# K1921VG015 register map
Vendor: NIIET; Series: K1921Vxxx; File version: 1.14
Registers are 32-bit, read-write, reset 0x0 unless marked. A register's access mark holds for its fields unless they carry their own. Offsets are from the block's base; [hi:lo] are bit positions; lines under a group give offsets from that group; {n}, {i} and the like mark numbered series; 'fields as' and 'values as' point back to an identical list.

## IWDT — Watchdog control registers
Base 0x38012000
0x00 LOAD — Watchdog Load Register
  [31:0] VAL
0x04 VALUE ro — Watchdog Value Register
  [31:0] VAL
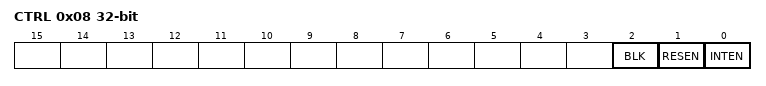
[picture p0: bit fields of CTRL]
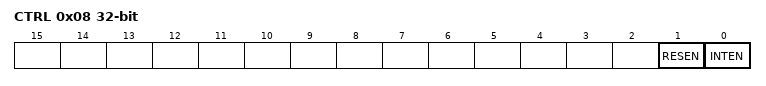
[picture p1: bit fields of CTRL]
0x08 CTRL — Watchdog Control Register
  [2] BLK — Blocking configuration
  [1] RESEN — Enable watchdog reset output
  [0] INTEN — Enable the interrupt event
0x0C INTCLR wo — Watchdog Clear Interrupt Register
  [31:0] WDTCLR
0x10 RIS ro — Watchdog Raw Interrupt Status Register
  [0] RAWWDTINT — Raw interrupt status from the counter
0x14 MIS ro — Watchdog Interrupt Status Register
  [0] WDTINT — Enabled interrupt status from the counter
0xC00 LOCK wo — Watchdog Lock Register
  [0] REGWRDIS — Disable write to all registers Watchdog

## WDT — Watchdog control registers
Base 0x3000B000
Registers as IWDT; these are added or differ:
0x08 CTRL — Watchdog Control Register
  [1] RESEN — Enable watchdog reset output
  [0] INTEN — Enable the interrupt event
0x0C INTCLR wo — Watchdog Clear Interrupt Register
  [31:0] WDTCLR
0x14 MIS ro — Watchdog Interrupt Status Register
  [0] WDTINT — Enabled interrupt status from the counter

## TMR0 — TMR 16-bit controller registers
Base 0x30001000
Same registers: TMR1 0x30002000, TMR2 0x30003000
0x00 CTRL — Timer control register
  [8] CLKSEL — Clock Source Select
    0=SysClk (Select system Clk); 1=ExtClk (Select External Clk)
  [7:6] DIV — Divider
    0=Clock not divided; 1=Clock divided by 2; 2=Clock divided by 4; 3=Clock divided by 8
  [5:4] MODE — Count mode
    0=Stop (Timer is Stopped); 1=Up (Timer count Up); 2=Multiple (Timer count is multiple Up); 3=UpDown (Timer count is multiple Up - Down)
  [2] CLR — Timer Clear
0x04 COUNT — Current value timer register
  [15:0] VAL
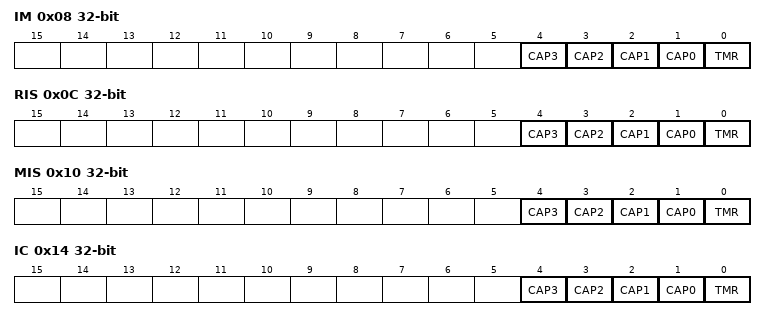
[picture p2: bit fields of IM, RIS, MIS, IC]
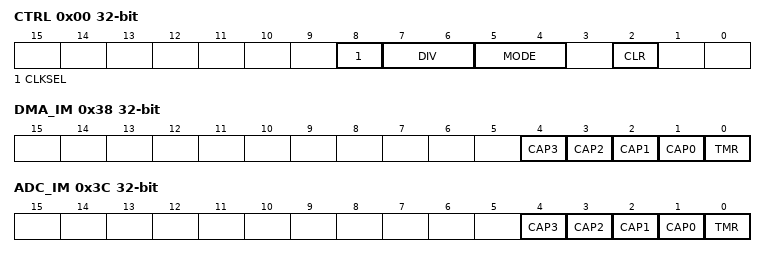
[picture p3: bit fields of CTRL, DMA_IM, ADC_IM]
0x08 IM — Interrupt mask register
  [n+1] CAP{n} (n=0..3) — Capcom{n} Interrupt Enable
  [0] TMR — Timer Interrupt Enable
0x0C RIS ro — Raw Interrupt Status register
  [n+1] CAP{n} (n=0..3) — Capcom{n} Interrupt Status
  [0] TMR — Timer Interrupt Status
0x10 MIS ro — Masked Interrupt Status register
  fields as RIS
0x14 IC wo — Clear Interrupt Status register
  [n+1] CAP{n} (n=0..3) — Capcom{n} Interrupt Clear
  [0] TMR — Timer Interrupt Clear
{0x18+8i} CAPCOM[{i}] (i=0..3) group
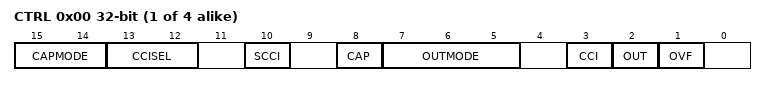
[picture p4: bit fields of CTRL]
  0x00 CTRL — Capture / Compare Control register
    [15:14] CAPMODE — Capture Mode
    [13:12] CCISEL — Capture / Compare Input Select
    [10] SCCI ro — Synchronized Capture / Compare Input
    [8] CAP — Capture Mode
    [7:5] OUTMODE — Output Mode
    [3] CCI ro — Capture / Compare Input
    [2] OUT — Output
    [1] OVF — Capture Overflow
  0x04 VAL 16-bit — Capture/Compare Value
0x38 DMA_IM — DMA request mask register
  [n+1] CAP{n} (n=0..3) — Capcom{n} DMA Request Enable
  [0] TMR — Timer DMA Request Enable
0x3C ADC_IM — ADC request mask register
  [n+1] CAP{n} (n=0..3) — Capcom{n} ADC Request Enable
  [0] TMR — Timer ADC Request Enable

## TMR32 — TMR 32-bit controller registers
Base 0x30000000
Registers as TMR0; these are added or differ:
0x04 COUNT — Current value timer register
  [31:0] VAL
{0x18+8i} CAPCOM[{i}] (i=0..3) group
  0x00 CTRL — Capture / Compare Control register
    fields as TMR0.CAPCOM[0].CTRL
  0x04 VAL — Capture/Compare Value

## CRC0 — CRC controller registers
Base 0x20030000
Same registers: CRC1 0x20031000
0x00 DR — CRC Data register
  [31:0] VAL — Data register
0x04 POST ro — CRC post register
  [31:0] VAL — Post-processing CRC value
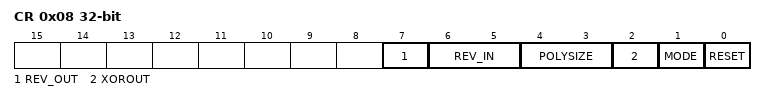
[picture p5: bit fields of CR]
0x08 CR — CRC control register
  [7] REV_OUT — Reverse output data
    0=Disable (Bit order not affected); 1=Enable (Bit-reversed output format)
  [6:5] REV_IN — Reverse input data. These bits control the reversal of the bit order of the input data
    0=Disable (Bit order not affected(default)); 1=REV_BYTE (Bit reversal done by byte); 2=REV_HALFWORD (Bit reversal done by half-word); 3=REV_WORD (Bit reversal done by word)
  [4:3] POLYSIZE — Polynomial size. These bits control the size of the polynomial
    0=POL32 (32 bit polynomial); 1=POL16 (16 bit polynomial); 2=POL8 (8 bit polynomial); 3=POL7 (7 bit polynomial)
  [2] XOROUT — XOR for data out
    0=Disable (Output XOR operation is disabled); 1=Enable (Output XOR operation is enabled)
  [1] MODE — Mode calc CRC
    0=StandartCRC (Standart mode); 1=STM32_CRC (STM32 compatible mode)
  [0] RESET wo — RESET bit
0x0C INIT — CRC initial value register
  [31:0] VAL — Initial CRC value
0x10 POL — CRC polynomial register
  [31:0] VAL — Programmable polynomial value
